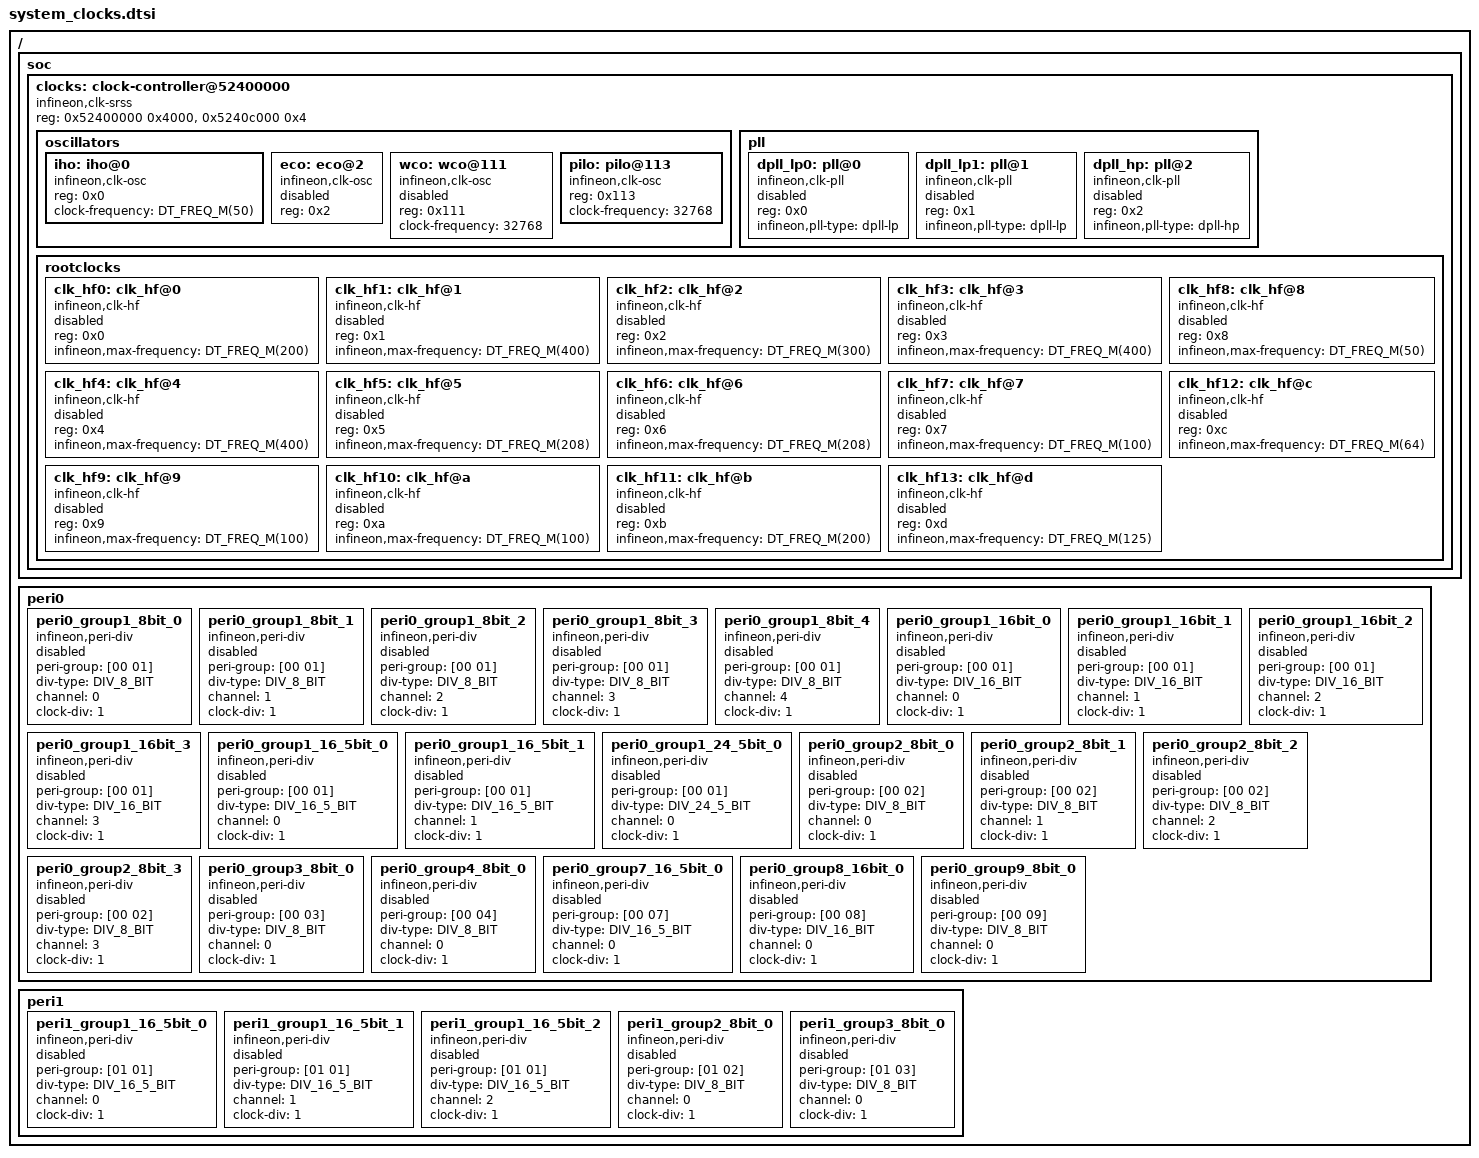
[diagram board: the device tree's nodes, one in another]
/*
 * SPDX-FileCopyrightText: Copyright (c) 2026 Infineon Technologies AG,
 * SPDX-FileCopyrightText: or an affiliate of Infineon Technologies AG. All rights reserved.
 *
 * SPDX-License-Identifier: Apache-2.0
 */

#define DIV_8_BIT    00
#define DIV_16_BIT	 01
#define DIV_16_5_BIT 02
#define DIV_24_5_BIT 03

#include <freq.h>
#include <zephyr/dt-bindings/clock/ifx_clock_source_common.h>
#include <zephyr/dt-bindings/clock/ifx_clock_source_pse8xx.h>

/ {
	soc {
		clocks: clock-controller@52400000 {
			compatible = "infineon,clk-srss";
			reg = <0x52400000 0x4000>, <0x5240c000 0x4>;
			reg-names = "srss", "wdt";

			oscillators {
				#address-cells = <1>;
				#size-cells = <0>;

				iho: iho@0 {
					compatible = "infineon,clk-osc";
					reg = <0x0>;
					#clock-cells = <0>;
					clock-frequency = <DT_FREQ_M(50)>;
					status = "okay";
				};

				eco: eco@2 {
					compatible = "infineon,clk-osc";
					reg = <0x2>;
					#clock-cells = <0>;
					status = "disabled";
				};

				wco: wco@111 {
					compatible = "infineon,clk-osc";
					reg = <0x111>;
					#clock-cells = <0>;
					clock-frequency = <32768>;
					status = "disabled";
				};

				pilo: pilo@113 {
					compatible = "infineon,clk-osc";
					reg = <0x113>;
					#clock-cells = <0>;
					clock-frequency = <32768>;
					status = "okay";
				};
			};

			pll {
				#address-cells = <1>;
				#size-cells = <0>;

				dpll_lp0: pll@0 {
					compatible = "infineon,clk-pll";
					reg = <0x0>;
					#clock-cells = <0>;
					infineon,pll-type = "dpll-lp";
					status = "disabled";
				};

				dpll_lp1: pll@1 {
					compatible = "infineon,clk-pll";
					reg = <0x1>;
					#clock-cells = <0>;
					infineon,pll-type = "dpll-lp";
					status = "disabled";
				};

				dpll_hp: pll@2 {
					compatible = "infineon,clk-pll";
					reg = <0x2>;
					#clock-cells = <0>;
					infineon,pll-type = "dpll-hp";
					status = "disabled";
				};
			};

			rootclocks {
				#address-cells = <1>;
				#size-cells = <0>;

				clk_hf0: clk_hf@0 {
					compatible = "infineon,clk-hf";
					reg = <0x0>;
					#clock-cells = <0>;
					infineon,max-frequency =
						<DT_FREQ_M(200)>;
					status = "disabled";
				};

				clk_hf1: clk_hf@1 {
					compatible = "infineon,clk-hf";
					reg = <0x1>;
					#clock-cells = <0>;
					infineon,max-frequency =
						<DT_FREQ_M(400)>;
					status = "disabled";
				};

				clk_hf2: clk_hf@2 {
					compatible = "infineon,clk-hf";
					reg = <0x2>;
					#clock-cells = <0>;
					infineon,max-frequency =
						<DT_FREQ_M(300)>;
					status = "disabled";
				};

				clk_hf3: clk_hf@3 {
					compatible = "infineon,clk-hf";
					reg = <0x3>;
					#clock-cells = <0>;
					infineon,max-frequency =
						<DT_FREQ_M(400)>;
					status = "disabled";
				};

				clk_hf4: clk_hf@4 {
					compatible = "infineon,clk-hf";
					reg = <0x4>;
					#clock-cells = <0>;
					infineon,max-frequency =
						<DT_FREQ_M(400)>;
					status = "disabled";
				};

				clk_hf5: clk_hf@5 {
					compatible = "infineon,clk-hf";
					reg = <0x5>;
					#clock-cells = <0>;
					infineon,max-frequency =
						<DT_FREQ_M(208)>;
					status = "disabled";
				};

				clk_hf6: clk_hf@6 {
					compatible = "infineon,clk-hf";
					reg = <0x6>;
					#clock-cells = <0>;
					infineon,max-frequency =
						<DT_FREQ_M(208)>;
					status = "disabled";
				};

				clk_hf7: clk_hf@7 {
					compatible = "infineon,clk-hf";
					reg = <0x7>;
					#clock-cells = <0>;
					infineon,max-frequency =
						<DT_FREQ_M(100)>;
					status = "disabled";
				};

				clk_hf8: clk_hf@8 {
					compatible = "infineon,clk-hf";
					reg = <0x8>;
					#clock-cells = <0>;
					infineon,max-frequency =
						<DT_FREQ_M(50)>;
					status = "disabled";
				};

				clk_hf9: clk_hf@9 {
					compatible = "infineon,clk-hf";
					reg = <0x9>;
					#clock-cells = <0>;
					infineon,max-frequency =
						<DT_FREQ_M(100)>;
					status = "disabled";
				};

				clk_hf10: clk_hf@a {
					compatible = "infineon,clk-hf";
					reg = <0xa>;
					#clock-cells = <0>;
					infineon,max-frequency =
						<DT_FREQ_M(100)>;
					status = "disabled";
				};

				clk_hf11: clk_hf@b {
					compatible = "infineon,clk-hf";
					reg = <0xb>;
					#clock-cells = <0>;
					infineon,max-frequency =
						<DT_FREQ_M(200)>;
					status = "disabled";
				};

				clk_hf12: clk_hf@c {
					compatible = "infineon,clk-hf";
					reg = <0xc>;
					#clock-cells = <0>;
					infineon,max-frequency =
						<DT_FREQ_M(64)>;
					status = "disabled";
				};

				clk_hf13: clk_hf@d {
					compatible = "infineon,clk-hf";
					reg = <0xd>;
					#clock-cells = <0>;
					infineon,max-frequency =
						<DT_FREQ_M(125)>;
					status = "disabled";
				};
			};
		};
	};

	peri0: peri0 {
		/* Peripheral 0, Clock Group 1 */
		/* 8-bit */
		peri0_group1_8bit_0: peri0_group1_8bit_0 {
			compatible = "infineon,peri-div";
			#clock-cells = <0>;
			peri-group = [00 01]; /* inst#, group# */
			div-type = <DIV_8_BIT>;
			channel = <0>;
			clock-div = <1>;
			status = "disabled";
		};

		peri0_group1_8bit_1: peri0_group1_8bit_1 {
			compatible = "infineon,peri-div";
			#clock-cells = <0>;
			peri-group = [00 01]; /* inst#, group# */
			div-type = <DIV_8_BIT>;
			channel = <1>;
			clock-div = <1>;
			status = "disabled";
		};

		peri0_group1_8bit_2: peri0_group1_8bit_2 {
			compatible = "infineon,peri-div";
			#clock-cells = <0>;
			peri-group = [00 01]; /* inst#, group# */
			div-type = <DIV_8_BIT>;
			channel = <2>;
			clock-div = <1>;
			status = "disabled";
		};

		peri0_group1_8bit_3: peri0_group1_8bit_3 {
			compatible = "infineon,peri-div";
			#clock-cells = <0>;
			peri-group = [00 01]; /* inst#, group# */
			div-type = <DIV_8_BIT>;
			channel = <3>;
			clock-div = <1>;
			status = "disabled";
		};

		peri0_group1_8bit_4: peri0_group1_8bit_4 {
			compatible = "infineon,peri-div";
			#clock-cells = <0>;
			peri-group = [00 01]; /* inst#, group# */
			div-type = <DIV_8_BIT>;
			channel = <4>;
			clock-div = <1>;
			status = "disabled";
		};

		/* 16-bit */
		peri0_group1_16bit_0: peri0_group1_16bit_0 {
			compatible = "infineon,peri-div";
			#clock-cells = <0>;
			peri-group = [00 01]; /* inst#, group# */
			div-type = <DIV_16_BIT>;
			channel = <0>;
			clock-div = <1>;
			status = "disabled";
		};

		peri0_group1_16bit_1: peri0_group1_16bit_1 {
			compatible = "infineon,peri-div";
			#clock-cells = <0>;
			peri-group = [00 01]; /* inst#, group# */
			div-type = <DIV_16_BIT>;
			channel = <1>;
			clock-div = <1>;
			status = "disabled";
		};

		peri0_group1_16bit_2: peri0_group1_16bit_2 {
			compatible = "infineon,peri-div";
			#clock-cells = <0>;
			peri-group = [00 01]; /* inst#, group# */
			div-type = <DIV_16_BIT>;
			channel = <2>;
			clock-div = <1>;
			status = "disabled";
		};

		peri0_group1_16bit_3: peri0_group1_16bit_3 {
			compatible = "infineon,peri-div";
			#clock-cells = <0>;
			peri-group = [00 01]; /* inst#, group# */
			div-type = <DIV_16_BIT>;
			channel = <3>;
			clock-div = <1>;
			status = "disabled";
		};

		/* 16.5-bit */
		peri0_group1_16_5bit_0: peri0_group1_16_5bit_0 {
			compatible = "infineon,peri-div";
			#clock-cells = <0>;
			peri-group = [00 01]; /* inst#, group# */
			div-type = <DIV_16_5_BIT>;
			channel = <0>;
			clock-div = <1>;
			status = "disabled";
		};

		peri0_group1_16_5bit_1: peri0_group1_16_5bit_1 {
			compatible = "infineon,peri-div";
			#clock-cells = <0>;
			peri-group = [00 01]; /* inst#, group# */
			div-type = <DIV_16_5_BIT>;
			channel = <1>;
			clock-div = <1>;
			status = "disabled";
		};

		/* 24.5-bit */
		peri0_group1_24_5bit_0: peri0_group1_24_5bit_0 {
			compatible = "infineon,peri-div";
			#clock-cells = <0>;
			peri-group = [00 01]; /* inst#, group# */
			div-type = <DIV_24_5_BIT>;
			channel = <0>;
			clock-div = <1>;
			status = "disabled";
		};

		/* Peripheral 0, Clock Group 2 */
		/* 8-bit */
		peri0_group2_8bit_0: peri0_group2_8bit_0 {
			compatible = "infineon,peri-div";
			#clock-cells = <0>;
			peri-group = [00 02]; /* inst#, group# */
			div-type = <DIV_8_BIT>;
			channel = <0>;
			clock-div = <1>;
			status = "disabled";
		};

		peri0_group2_8bit_1: peri0_group2_8bit_1 {
			compatible = "infineon,peri-div";
			#clock-cells = <0>;
			peri-group = [00 02]; /* inst#, group# */
			div-type = <DIV_8_BIT>;
			channel = <1>;
			clock-div = <1>;
			status = "disabled";
		};

		peri0_group2_8bit_2: peri0_group2_8bit_2 {
			compatible = "infineon,peri-div";
			#clock-cells = <0>;
			peri-group = [00 02]; /* inst#, group# */
			div-type = <DIV_8_BIT>;
			channel = <2>;
			clock-div = <1>;
			status = "disabled";
		};

		peri0_group2_8bit_3: peri0_group2_8bit_3 {
			compatible = "infineon,peri-div";
			#clock-cells = <0>;
			peri-group = [00 02]; /* inst#, group# */
			div-type = <DIV_8_BIT>;
			channel = <3>;
			clock-div = <1>;
			status = "disabled";
		};

		/* Peripheral 0, Clock Group 3 */
		/* 8-bit */
		peri0_group3_8bit_0: peri0_group3_8bit_0 {
			compatible = "infineon,peri-div";
			#clock-cells = <0>;
			peri-group = [00 03]; /* inst#, group# */
			div-type = <DIV_8_BIT>;
			channel = <0>;
			clock-div = <1>;
			status = "disabled";
		};

		/* Peripheral 0, Clock Group 4 */
		/* 8-bit */
		peri0_group4_8bit_0: peri0_group4_8bit_0 {
			compatible = "infineon,peri-div";
			#clock-cells = <0>;
			peri-group = [00 04]; /* inst#, group# */
			div-type = <DIV_8_BIT>;
			channel = <0>;
			clock-div = <1>;
			status = "disabled";
		};

		/* Peripheral 0, Clock Group 7 */
		/* 16.5-bit */
		peri0_group7_16_5bit_0: peri0_group7_16_5bit_0 {
			compatible = "infineon,peri-div";
			#clock-cells = <0>;
			peri-group = [00 07]; /* inst#, group# */
			div-type = <DIV_16_5_BIT>;
			channel = <0>;
			clock-div = <1>;
			status = "disabled";
		};

		/* Peripheral 0, Clock Group 8 */
		/* 16-bit */
		peri0_group8_16bit_0: peri0_group8_16bit_0 {
			compatible = "infineon,peri-div";
			#clock-cells = <0>;
			peri-group = [00 08]; /* inst#, group# */
			div-type = <DIV_16_BIT>;
			channel = <0>;
			clock-div = <1>;
			status = "disabled";
		};

		/* Peripheral 0, Clock Group 9 */
		/* 8-bit */
		peri0_group9_8bit_0: peri0_group9_8bit_0 {
			compatible = "infineon,peri-div";
			#clock-cells = <0>;
			peri-group = [00 09]; /* inst#, group# */
			div-type = <DIV_8_BIT>;
			channel = <0>;
			clock-div = <1>;
			status = "disabled";
		};
	};

	peri1: peri1 {
		/* Peripheral 1, Clock Group 1 */
		/* 16.5-bit */
		peri1_group1_16_5bit_0: peri1_group1_16_5bit_0 {
			compatible = "infineon,peri-div";
			#clock-cells = <0>;
			peri-group = [01 01]; /* inst#, group# */
			div-type = <DIV_16_5_BIT>;
			channel = <0>;
			clock-div = <1>;
			status = "disabled";
		};

		peri1_group1_16_5bit_1: peri1_group1_16_5bit_1 {
			compatible = "infineon,peri-div";
			#clock-cells = <0>;
			peri-group = [01 01]; /* inst#, group# */
			div-type = <DIV_16_5_BIT>;
			channel = <1>;
			clock-div = <1>;
			status = "disabled";
		};

		peri1_group1_16_5bit_2: peri1_group1_16_5bit_2 {
			compatible = "infineon,peri-div";
			#clock-cells = <0>;
			peri-group = [01 01]; /* inst#, group# */
			div-type = <DIV_16_5_BIT>;
			channel = <2>;
			clock-div = <1>;
			status = "disabled";
		};

		/* Peripheral 1, Clock Group 2 */
		/* 8-bit */
		peri1_group2_8bit_0: peri1_group2_8bit_0 {
			compatible = "infineon,peri-div";
			#clock-cells = <0>;
			peri-group = [01 02]; /* inst#, group# */
			div-type = <DIV_8_BIT>;
			channel = <0>;
			clock-div = <1>;
			status = "disabled";
		};

		/* Peripheral 1, Clock Group 3 */
		/* 8-bit */
		peri1_group3_8bit_0: peri1_group3_8bit_0 {
			compatible = "infineon,peri-div";
			#clock-cells = <0>;
			peri-group = [01 03]; /* inst#, group# */
			div-type = <DIV_8_BIT>;
			channel = <0>;
			clock-div = <1>;
			status = "disabled";
		};
	};
};
